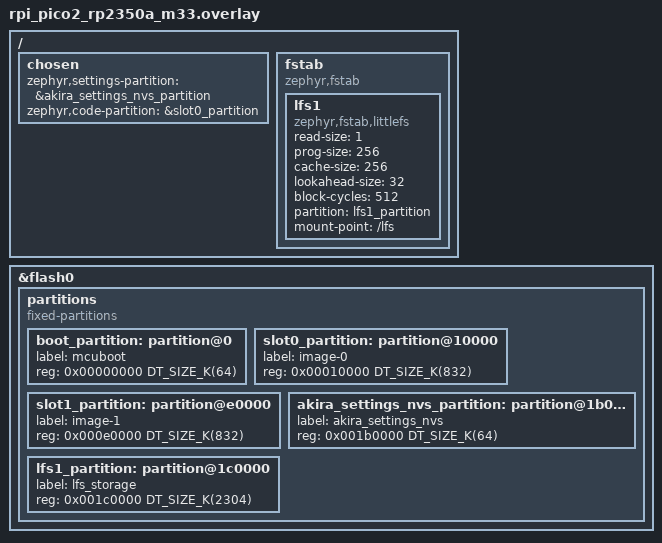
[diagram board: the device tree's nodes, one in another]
/*
 * Raspberry Pi Pico 2 (RP2350) DTS overlay for AkiraOS
 * Board: rpi_pico2
 *
 * RP2350 has 4 MB external QSPI Flash (W25Q32JV on standard Pico 2).
 * Partition layout:
 *   64 KB  — MCUBoot (optional)
 *   2 MB   — Application slot-0
 *   32 KB  — AkiraOS NVS settings
 *   128 KB — LittleFS WASM app storage
 */

/ {
    chosen {
        zephyr,settings-partition = &akira_settings_nvs_partition;
        zephyr,code-partition = &slot0_partition;
    };

    fstab {
        compatible = "zephyr,fstab";

        lfs1: lfs1 {
            compatible = "zephyr,fstab,littlefs";
            read-size = <1>;
            prog-size = <256>;
            cache-size = <256>;
            lookahead-size = <32>;
            block-cycles = <512>;
            partition = <&lfs1_partition>;
            mount-point = "/lfs";
        };
    };
};

/*
 * RP2350 4 MB flash (&flash0). AkiraOS builds MCUboot images
 * (CONFIG_BOOTLOADER_MCUBOOT=y); the upstream non-MCUboot board defines no
 * partitions, so lay out the full MCUboot table (mirroring
 * partitions_4M_sysbuild.dtsi) — boot + equal slot0/slot1 — plus AkiraOS
 * settings-NVS + LittleFS. The app is linked into slot0.
 */
&flash0 {
    partitions {
        compatible = "fixed-partitions";
        #address-cells = <1>;
        #size-cells = <1>;

        boot_partition: partition@0 {
            label = "mcuboot";
            reg = <0x00000000 DT_SIZE_K(64)>;
        };

        slot0_partition: partition@10000 {
            label = "image-0";
            reg = <0x00010000 DT_SIZE_K(832)>;
        };

        slot1_partition: partition@e0000 {
            label = "image-1";
            reg = <0x000e0000 DT_SIZE_K(832)>;
        };

        akira_settings_nvs_partition: partition@1b0000 {
            label = "akira_settings_nvs";
            reg = <0x001b0000 DT_SIZE_K(64)>;
        };

        lfs1_partition: partition@1c0000 {
            label = "lfs_storage";
            reg = <0x001c0000 DT_SIZE_K(2304)>;
        };
    };
};
